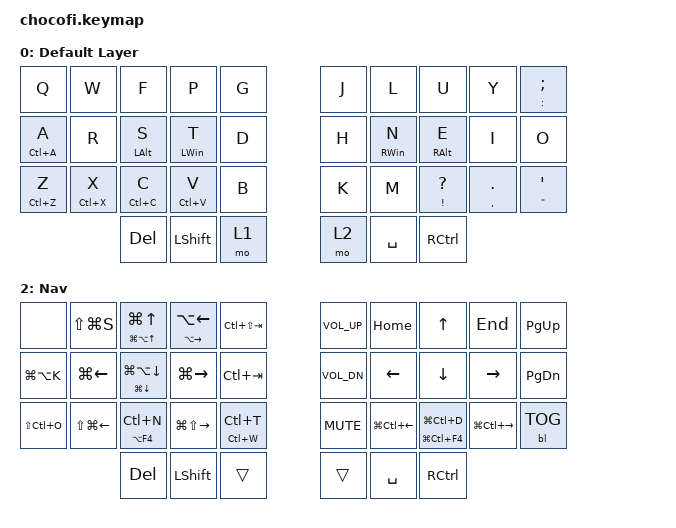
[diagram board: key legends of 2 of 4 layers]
/*
 * Copyright (c) 2020 The ZMK Contributors
 *
 * SPDX-License-Identifier: MIT
 */

#include <behaviors.dtsi>
#include <dt-bindings/zmk/backlight.h>
#include <dt-bindings/zmk/bt.h>
#include <dt-bindings/zmk/keys.h>
#include <dt-bindings/zmk/pointing.h>

/ {
    combos {
        compatible = "zmk,combos";

        SettingLayer {
            bindings = <&mo 3>;
            key-positions = <26 27>;
            layers = <1 2 3 0>;
        };

        Esc_combo {
            bindings = <&kp ESC>;
            key-positions = <1 2>;
            layers = <1 0 2 3>;
        };

        Tab_combo {
            bindings = <&kp TAB>;
            key-positions = <16 17>;
            layers = <1 2 0 3>;
        };

        Bspace_combo {
            bindings = <&kp BACKSPACE>;
            key-positions = <5 6>;
            layers = <0 2 3 1>;
        };

        Enter_combo {
            bindings = <&kp ENTER>;
            key-positions = <21 22>;
            layers = <3 0 1 2>;
        };

        LC_combo {
            bindings = <&mkp LCLK>;
            key-positions = <11 12>;
            layers = <3 2 1 0>;
        };

        RC_combo {
            bindings = <&mkp RCLK>;
            key-positions = <3 4>;
            layers = <0 2 3 1>;
        };
    };

    keymap {
        compatible = "zmk,keymap";

        default_layer {
            display-name = "Default Layer";

            // -----------------------------------------------------------------------------------------
            // |  Q  |  W  |  F  |  P  |  G  |   |  J  |  L  |  U  |  Y  |  ;  |
            // |  A  |  R  |  S  |  T  |  D  |   |  H  |  N  |  E  |  I  |  O  |
            // |  Z  |  X  |  C  |  V  |  B  |   |  K  |  M  |  .  |  ?  |  '  |
            //             | DEL | SFT | NUM |   | NAV | SPC | CTL |

            bindings = <
&kp Q        &kp W        &kp F           &kp P           &kp G        &kp J        &kp L        &kp U        &kp Y        &mt COLON SEMI
&mt LC(A) A  &kp R        &mt LEFT_ALT S  &mt LEFT_WIN T  &kp D        &kp H        &mt RIGHT_WIN N  &mt RIGHT_ALT E  &kp I        &kp O
&mt LC(Z) Z  &mt LC(X) X  &mt LC(C) C     &mt LC(V) V     &kp B        &kp K        &kp M        &mt EXCL QUESTION  &mt COMMA PERIOD  &mt DOUBLE_QUOTES SINGLE_QUOTE
             &kp DEL      &kp LEFT_SHIFT  &mo 1           &mo 2        &kp SPACE    &kp RCTRL
            >;

            label = "Alpha";
        };

        lower_layer {
            display-name = "Num";

            bindings = <
&kp TILDE    &kp AMPS     &kp HASH       &mt RIGHT_BRACE LEFT_BRACE  &mt GT LT        &kp LS(LA(LC(C)))  &kp N7        &kp N8        &kp NUMBER_9  &kp MINUS
&kp PERCENT  &kp EXCL     &kp DOLLAR     &kp AT                      &mt RPAR LPAR    &kp PERIOD         &kp NUMBER_4  &kp NUMBER_5  &kp NUMBER_6  &kp PLUS
&kp GRAVE    &kp PIPE     &kp BACKSLASH  &kp UNDERSCORE              &mt RBKT LBKT    &kp NUMBER_0       &kp NUMBER_1  &kp NUMBER_2  &kp NUMBER_3  &kp SLASH
             &kp DEL      &kp LEFT_SHIFT &trans                      &trans           &kp SPACE          &kp RCTRL
            >;
        };

        raise_layer {
            display-name = "Nav";

            bindings = <
&none          &kp LS(LG(S))     &mt LG(LA(UP)) LG(UP_ARROW)  &mt LA(RIGHT) LA(LEFT)  &kp LC(LS(TAB))    &kp C_VOLUME_UP  &kp HOME  &kp UP  &kp END  &kp PAGE_UP
&kp LG(LA(K))  &kp LG(LEFT)      &mt LG(DOWN) LG(LA(DOWN))    &kp LG(RIGHT)           &kp LC(TAB)        &kp C_VOL_DN     &kp LEFT  &kp DOWN &kp RIGHT &kp PAGE_DOWN
&kp LS(LC(O))  &kp LS(LG(LEFT))  &mt LA(F4) LC(N)             &kp LG(LS(RIGHT))       &mt LC(W) LC(T)    &kp C_MUTE       &kp LG(LC(LEFT)) &mt LG(LC(F4)) LG(LC(D)) &kp LG(LC(RIGHT)) &bl BL_TOG
                &kp DEL          &kp LSHFT                    &trans                  &trans             &kp SPACE        &kp RCTRL
            >;
        };

        layer_3 {
            display-name = "Bluetooth";

            bindings = <
&trans  &trans  &trans  &trans  &bt BT_CLR   &bt BT_SEL 0    &trans  &trans  &trans  &trans
&trans  &trans  &trans  &trans  &bt BT_SEL 1 &bt BT_SEL 2    &trans  &trans  &trans  &trans
&trans  &trans  &trans  &trans  &trans       &trans          &trans  &trans  &trans  &trans
            >;
        };
    };
};
